VERSION ""

NS_ :

BS_:

BU_: SUT Tester

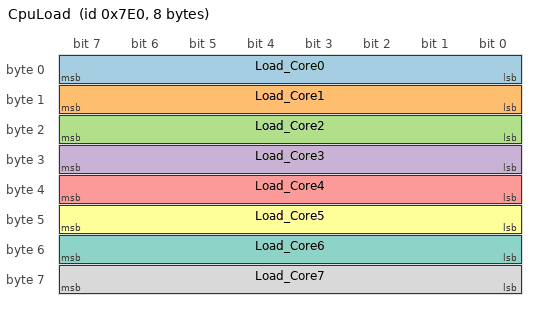
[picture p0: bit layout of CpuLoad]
BO_ 2016 CpuLoad: 8 SUT
 SG_ Load_Core0 : 0|8@1+ (1,0) [0|100] "%" Tester
 SG_ Load_Core1 : 8|8@1+ (1,0) [0|100] "%" Tester
 SG_ Load_Core2 : 16|8@1+ (1,0) [0|100] "%" Tester
 SG_ Load_Core3 : 24|8@1+ (1,0) [0|100] "%" Tester
 SG_ Load_Core4 : 32|8@1+ (1,0) [0|100] "%" Tester
 SG_ Load_Core5 : 40|8@1+ (1,0) [0|100] "%" Tester
 SG_ Load_Core6 : 48|8@1+ (1,0) [0|100] "%" Tester
 SG_ Load_Core7 : 56|8@1+ (1,0) [0|100] "%" Tester

BO_ 784 ButtonState: 4 SUT
 SG_ BtnPressed : 0|32@1+ (1,0) [0|1] "" Tester

BA_DEF_ BO_ "GenMsgCycleTime" INT 0 100000;
BA_DEF_DEF_ "GenMsgCycleTime" 0;
BA_ "GenMsgCycleTime" BO_ 2016 1000;
